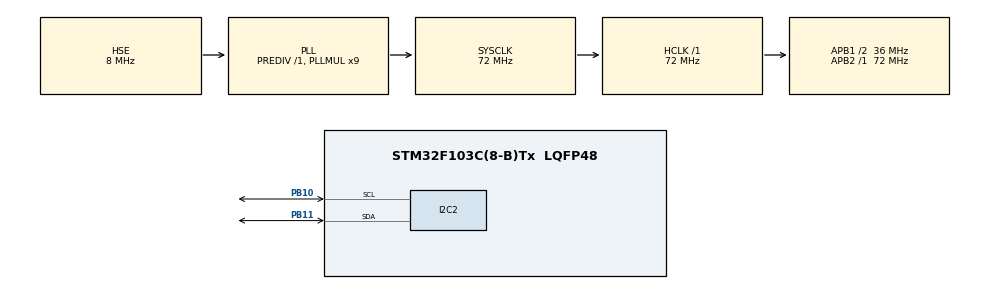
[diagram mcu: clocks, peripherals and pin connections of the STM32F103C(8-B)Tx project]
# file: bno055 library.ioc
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Dma.I2C2_RX.1.Direction=DMA_PERIPH_TO_MEMORY
Dma.I2C2_RX.1.Instance=DMA1_Channel5
Dma.I2C2_RX.1.MemDataAlignment=DMA_MDATAALIGN_BYTE
Dma.I2C2_RX.1.MemInc=DMA_MINC_ENABLE
Dma.I2C2_RX.1.Mode=DMA_NORMAL
Dma.I2C2_RX.1.PeriphDataAlignment=DMA_PDATAALIGN_BYTE
Dma.I2C2_RX.1.PeriphInc=DMA_PINC_DISABLE
Dma.I2C2_RX.1.Priority=DMA_PRIORITY_HIGH
Dma.I2C2_TX.0.Direction=DMA_MEMORY_TO_PERIPH
Dma.I2C2_TX.0.Instance=DMA1_Channel4
Dma.I2C2_TX.0.MemDataAlignment=DMA_MDATAALIGN_BYTE
Dma.I2C2_TX.0.MemInc=DMA_MINC_ENABLE
Dma.I2C2_TX.0.Mode=DMA_NORMAL
Dma.I2C2_TX.0.PeriphDataAlignment=DMA_PDATAALIGN_BYTE
Dma.I2C2_TX.0.PeriphInc=DMA_PINC_DISABLE
Dma.I2C2_TX.0.Priority=DMA_PRIORITY_HIGH
Dma.Request0=I2C2_TX
Dma.Request1=I2C2_RX
I2C2.I2C_Mode=I2C_Fast
Mcu.Family=STM32F1
Mcu.Name=STM32F103C(8-B)Tx
Mcu.Package=LQFP48
NVIC.DMA1_Channel4_IRQn=true\:0\:0\:false\:false\:true\:false\:true\:true
NVIC.DMA1_Channel5_IRQn=true\:0\:0\:false\:false\:true\:false\:true\:true
NVIC.PriorityGroup=NVIC_PRIORITYGROUP_4
PA13.Mode=Serial_Wire
PA13.Signal=SYS_JTMS-SWDIO
PA14.Mode=Serial_Wire
PA14.Signal=SYS_JTCK-SWCLK
PB10.Mode=I2C
PB10.Signal=I2C2_SCL
PB11.Mode=I2C
PB11.Signal=I2C2_SDA
PD0-OSC_IN.Mode=HSE-External-Oscillator
PD0-OSC_IN.Signal=RCC_OSC_IN
PD1-OSC_OUT.Mode=HSE-External-Oscillator
PD1-OSC_OUT.Signal=RCC_OSC_OUT
ProjectManager.HeapSize=0x200
ProjectManager.StackSize=0x400
ProjectManager.TargetToolchain=MDK-ARM V5.32
RCC.AHBFreq_Value=72000000
RCC.APB1CLKDivider=RCC_HCLK_DIV2
RCC.APB1Freq_Value=36000000
RCC.APB1TimFreq_Value=72000000
RCC.APB2Freq_Value=72000000
RCC.APB2TimFreq_Value=72000000
RCC.HCLKFreq_Value=72000000
RCC.PLLMUL=RCC_PLL_MUL9
RCC.PLLSourceVirtual=RCC_PLLSOURCE_HSE
RCC.SYSCLKFreq_VALUE=72000000
RCC.SYSCLKSource=RCC_SYSCLKSOURCE_PLLCLK
RCC.USBFreq_Value=72000000
board=custom

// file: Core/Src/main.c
/* USER CODE BEGIN Header */
/**
  ******************************************************************************
  * @file           : main.c
  * @brief          : Main program body
  ******************************************************************************
  * @attention
  *
  * Copyright (c) 2023 STMicroelectronics.
  * All rights reserved.
  *
  * This software is licensed under terms that can be found in the LICENSE file
  * in the root directory of this software component.
  * If no LICENSE file comes with this software, it is provided AS-IS.
  *
  ******************************************************************************
  */
/* USER CODE END Header */
#include "main.h"

/* USER CODE BEGIN Includes */
#include "bno055.h"
/* USER CODE END Includes */

/* USER CODE BEGIN PD */
//#define BNO055_I2C_ADDRESS (0x29 << 1)
/* USER CODE END PD */

I2C_HandleTypeDef hi2c2;
DMA_HandleTypeDef hdma_i2c2_tx;
DMA_HandleTypeDef hdma_i2c2_rx;

void SystemClock_Config(void);
static void MX_GPIO_Init(void);
static void MX_DMA_Init(void);
static void MX_I2C2_Init(void);

/* USER CODE BEGIN 0 */
BNO055_vector vec;
BNO055_calibration cal;
uint8_t status;
uint8_t BNO055_ADDR;
uint8_t selftest;
uint8_t calibrationStatus;
uint8_t i2cOK;

/* USER CODE END 0 */

int main(void)
{

  /* MCU Configuration--------------------------------------------------------*/

  /* Reset of all peripherals, Initializes the Flash interface and the Systick. */
  HAL_Init();

  /* Configure the system clock */
  SystemClock_Config();

  /* Initialize all configured peripherals */
  MX_GPIO_Init();
  MX_DMA_Init();
  MX_I2C2_Init();
  /* USER CODE BEGIN 2 */
	BNO055_setup(&hi2c2);

	BNO055_WriteRegister(BNO055_OPR_MODE, BNO055_OPERATION_MODE_IMU);
	HAL_Delay(20);
	cal = BNO055_getVectorEulerCalibration();
//	status = BNO055_getSystemStatus();
  /* USER CODE END 2 */

  /* Infinite loop */
  while (1)
  {

    /* USER CODE BEGIN 3 */

		vec = BNO055_getVectorEuler();
//		vec.roll -= cal.rollCalibration;
//		vec.pitch -= cal.pitchCalibration;
//		vec.yaw -= cal.yawCalibration;

//		status = BNO055_getSystemStatus();
//		selftest = BNO055_getSelfTestStatus();
  }
  /* USER CODE END 3 */
}

void SystemClock_Config(void)
{
  RCC_OscInitTypeDef RCC_OscInitStruct = {0};
  RCC_ClkInitTypeDef RCC_ClkInitStruct = {0};

  /** Initializes the RCC Oscillators according to the specified parameters
  * in the RCC_OscInitTypeDef structure.
  */
  RCC_OscInitStruct.OscillatorType = RCC_OSCILLATORTYPE_HSE;
  RCC_OscInitStruct.HSEState = RCC_HSE_ON;
  RCC_OscInitStruct.HSEPredivValue = RCC_HSE_PREDIV_DIV1;
  RCC_OscInitStruct.HSIState = RCC_HSI_ON;
  RCC_OscInitStruct.PLL.PLLState = RCC_PLL_ON;
  RCC_OscInitStruct.PLL.PLLSource = RCC_PLLSOURCE_HSE;
  RCC_OscInitStruct.PLL.PLLMUL = RCC_PLL_MUL9;
  if (HAL_RCC_OscConfig(&RCC_OscInitStruct) != HAL_OK)
  {
    Error_Handler();
  }

  /** Initializes the CPU, AHB and APB buses clocks
  */
  RCC_ClkInitStruct.ClockType = RCC_CLOCKTYPE_HCLK|RCC_CLOCKTYPE_SYSCLK
                              |RCC_CLOCKTYPE_PCLK1|RCC_CLOCKTYPE_PCLK2;
  RCC_ClkInitStruct.SYSCLKSource = RCC_SYSCLKSOURCE_PLLCLK;
  RCC_ClkInitStruct.AHBCLKDivider = RCC_SYSCLK_DIV1;
  RCC_ClkInitStruct.APB1CLKDivider = RCC_HCLK_DIV2;
  RCC_ClkInitStruct.APB2CLKDivider = RCC_HCLK_DIV1;

  if (HAL_RCC_ClockConfig(&RCC_ClkInitStruct, FLASH_LATENCY_2) != HAL_OK)
  {
    Error_Handler();
  }
}

static void MX_I2C2_Init(void)
{

  hi2c2.Instance = I2C2;
  hi2c2.Init.ClockSpeed = 400000;
  hi2c2.Init.DutyCycle = I2C_DUTYCYCLE_2;
  hi2c2.Init.OwnAddress1 = 0;
  hi2c2.Init.AddressingMode = I2C_ADDRESSINGMODE_7BIT;
  hi2c2.Init.DualAddressMode = I2C_DUALADDRESS_DISABLE;
  hi2c2.Init.OwnAddress2 = 0;
  hi2c2.Init.GeneralCallMode = I2C_GENERALCALL_DISABLE;
  hi2c2.Init.NoStretchMode = I2C_NOSTRETCH_DISABLE;
  if (HAL_I2C_Init(&hi2c2) != HAL_OK)
  {
    Error_Handler();
  }

}

static void MX_DMA_Init(void)
{

  /* DMA controller clock enable */
  __HAL_RCC_DMA1_CLK_ENABLE();

  /* DMA interrupt init */
  /* DMA1_Channel4_IRQn interrupt configuration */
  HAL_NVIC_SetPriority(DMA1_Channel4_IRQn, 0, 0);
  HAL_NVIC_EnableIRQ(DMA1_Channel4_IRQn);
  /* DMA1_Channel5_IRQn interrupt configuration */
  HAL_NVIC_SetPriority(DMA1_Channel5_IRQn, 0, 0);
  HAL_NVIC_EnableIRQ(DMA1_Channel5_IRQn);

}

static void MX_GPIO_Init(void)
{

  /* GPIO Ports Clock Enable */
  __HAL_RCC_GPIOD_CLK_ENABLE();
  __HAL_RCC_GPIOB_CLK_ENABLE();
  __HAL_RCC_GPIOA_CLK_ENABLE();

}

void Error_Handler(void)
{
  __disable_irq();
  while (1)
  {
  }
}
